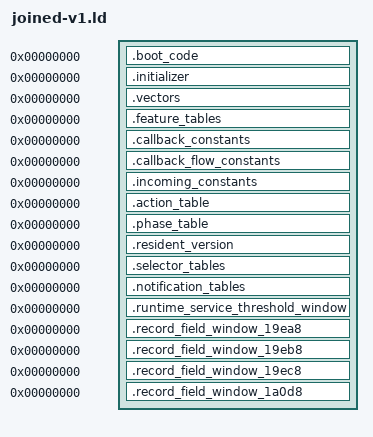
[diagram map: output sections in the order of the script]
OUTPUT_ARCH(riscv)
SECTIONS
{
 .boot_code 0 : SUBALIGN(2) { *(.boot_code)
  *(.text.tsl9_record_dispatch_provider_b584)
  *(.text.tsl9_remaining_record_dispatch_entry_b5f6)
  *(.text.tsl9_remaining_record_dispatch_block_b604)
  *(.text.tsl9_remaining_record_dispatch_block_b60a)
  *(.text.tsl9_remaining_record_dispatch_block_b616)
  *(.text.tsl9_remaining_record_dispatch_block_b618)
  *(.text.tsl9_remaining_record_dispatch_block_b628)
  *(.text.tsl9_remaining_record_dispatch_block_b63c)
  *(.text.tsl9_remaining_record_dispatch_block_b642)
  *(.text.tsl9_remaining_record_dispatch_block_b648)
  *(.text.tsl9_remaining_record_dispatch_block_b64e)
  *(.text.tsl9_remaining_record_dispatch_block_b650)
  *(.text.tsl9_remaining_record_dispatch_entry_b67a)
  *(.text.tsl9_remaining_record_dispatch_block_b680)
  *(.text.tsl9_remaining_record_dispatch_block_b68a)
  *(.text.tsl9_remaining_record_dispatch_block_b6a2)
  *(.text.tsl9_remaining_record_dispatch_entry_b6bc)
  *(.text.tsl9_remaining_record_dispatch_block_b6c2)
  *(.text.tsl9_remaining_record_dispatch_block_b6cc)
  *(.text.tsl9_remaining_record_dispatch_block_b6e4)
  *(.text.tsl9_feature_external_b730)
  *(.text.tsl9_remaining_record_dispatch_block_b744)
  *(.text.tsl9_remaining_record_dispatch_block_b74a)
  *(.text.tsl9_remaining_record_dispatch_block_b756)
  *(.text.tsl9_remaining_record_dispatch_block_b76a)
  *(.text.tsl9_remaining_record_dispatch_block_b776)
  *(.text.tsl9_remaining_record_dispatch_block_b790)
  *(.text.tsl9_remaining_record_dispatch_block_b7ac)
  *(.text.tsl9_remaining_record_dispatch_block_b7c6)
  *(.text.tsl9_remaining_record_dispatch_block_b7e2)
  *(.text.tsl9_remaining_record_dispatch_block_b7f0)
  *(.text.tsl9_remaining_record_dispatch_block_b800)
  *(.text.tsl9_remaining_record_dispatch_block_b808)
  *(.text.tsl9_remaining_record_dispatch_block_b80c)
  *(.text.tsl9_remaining_record_dispatch_block_b816)
  *(.text.tsl9_remaining_record_dispatch_block_b818)
  *(.text.tsl9_remaining_record_dispatch_block_b82c)
  *(.text.tsl9_remaining_record_dispatch_block_b838)
  *(.text.tsl9_remaining_record_dispatch_block_b846)
  *(.text.tsl9_remaining_record_dispatch_block_b84a)
  *(.text.tsl9_remaining_record_dispatch_block_b84e)
  *(.text.tsl9_remaining_record_dispatch_block_b85e)
  *(.text.tsl9_remaining_record_dispatch_block_b86e)
  *(.text.tsl9_remaining_record_dispatch_block_b872)
  *(.text.tsl9_remaining_record_dispatch_block_b878)
  *(.text.tsl9_remaining_record_dispatch_block_b890)
  *(.text.tsl9_remaining_record_dispatch_block_b892)
  *(.text.tsl9_remaining_record_dispatch_block_b898)
  *(.text.tsl9_remaining_record_dispatch_block_b89e)
  *(.text.tsl9_remaining_record_dispatch_block_b8ae)
  *(.text.tsl9_remaining_record_dispatch_block_b8b2)
  *(.text.tsl9_remaining_record_dispatch_block_b8b8)
  *(.text.tsl9_remaining_record_dispatch_block_b8c2)
  *(.text.tsl9_remaining_record_dispatch_block_b8c6)
  *(.text.tsl9_remaining_record_dispatch_block_b8cc)
  *(.text.tsl9_remaining_record_dispatch_block_b8d0)
  *(.text.tsl9_remaining_record_dispatch_block_b8da)
  *(.text.tsl9_remaining_record_dispatch_block_b8de)
  *(.text.tsl9_remaining_record_dispatch_block_b8e4)
  *(.text.tsl9_remaining_record_dispatch_block_b8e8)
  *(.text.tsl9_remaining_record_dispatch_block_b8ee)
  *(.text.tsl9_remaining_record_dispatch_block_b8f2)
  *(.text.tsl9_remaining_record_dispatch_block_b8f8)
  *(.text.tsl9_remaining_record_dispatch_block_b8fc)
  *(.text.tsl9_remaining_record_dispatch_block_b902)
  *(.text.tsl9_remaining_record_dispatch_block_b906)
  *(.text.tsl9_remaining_record_dispatch_block_b90c)
  *(.text.tsl9_remaining_record_dispatch_block_b910)
  *(.text.tsl9_remaining_record_dispatch_block_b91e)
  *(.text.tsl9_remaining_record_dispatch_block_b924)
  *(.text.tsl9_remaining_record_dispatch_block_b92e)
  *(.text.tsl9_remaining_record_dispatch_block_b934)
  *(.text.tsl9_remaining_record_dispatch_block_b940)
  *(.text.tsl9_remaining_record_dispatch_block_b946)
  *(.text.tsl9_remaining_record_dispatch_block_b952)
  *(.text.tsl9_remaining_record_dispatch_block_b958)
  *(.text.tsl9_remaining_record_dispatch_block_b964)
  *(.text.tsl9_remaining_record_dispatch_block_b96a)
  *(.text.tsl9_remaining_record_dispatch_block_b972)
  *(.text.tsl9_remaining_record_dispatch_block_b978)
  *(.text.tsl9_remaining_record_dispatch_block_b980)
  *(.text.tsl9_remaining_record_dispatch_block_b986)
  *(.text.tsl9_remaining_record_dispatch_block_b98e)
  *(.text.tsl9_remaining_record_dispatch_block_b994)
  *(.text.tsl9_remaining_record_dispatch_block_b9a0)
  *(.text.tsl9_remaining_record_dispatch_block_b9a4)
  *(.text.tsl9_remaining_record_dispatch_block_b9b0)
  *(.text.tsl9_remaining_record_dispatch_block_b9b4)
  *(.text.tsl9_remaining_record_dispatch_block_b9be)
  *(.text.tsl9_remaining_record_dispatch_block_b9c2)
  *(.text.tsl9_remaining_record_dispatch_block_b9ca)
  *(.text.tsl9_remaining_record_dispatch_block_b9ce)
  *(.text.tsl9_remaining_record_dispatch_block_b9d4)
  *(.text.tsl9_remaining_record_dispatch_block_b9e4)
  *(.text.tsl9_remaining_record_dispatch_block_b9f2)
  *(.text.tsl9_remaining_record_dispatch_block_b9fe)
  *(.text.tsl9_remaining_record_dispatch_block_ba02)
  *(.text.tsl9_remaining_record_dispatch_block_ba08)
  *(.text.tsl9_remaining_record_dispatch_block_ba14)
  *(.text.tsl9_remaining_record_dispatch_block_ba18)
  *(.text.tsl9_remaining_record_dispatch_block_ba1a)
  *(.text.tsl9_remaining_record_dispatch_block_ba20)
  *(.text.tsl9_remaining_record_dispatch_block_ba24)
  *(.text.tsl9_remaining_record_dispatch_block_ba28)
  *(.text.tsl9_remaining_record_dispatch_block_ba3a)
  *(.text.tsl9_remaining_record_dispatch_block_ba46)
  *(.text.tsl9_remaining_record_dispatch_block_ba4a)
  *(.text.tsl9_remaining_record_dispatch_block_ba50)
  *(.text.tsl9_remaining_record_dispatch_block_ba58)
  *(.text.tsl9_remaining_record_dispatch_block_ba5c)
  *(.text.tsl9_remaining_record_dispatch_block_ba70)
  *(.text.tsl9_remaining_record_dispatch_block_ba7e)
  *(.text.tsl9_remaining_record_dispatch_block_ba80)
  *(.text.tsl9_remaining_record_dispatch_block_ba94)
  *(.text.tsl9_remaining_record_dispatch_block_baa2)
  *(.text.tsl9_remaining_record_dispatch_block_baa4)
  *(.text.tsl9_remaining_record_dispatch_block_babe)
  *(.text.tsl9_remaining_record_dispatch_block_bac0)
  *(.text.tsl9_remaining_record_dispatch_block_bac4)
  *(.text.tsl9_remaining_record_dispatch_block_baca)
  *(.text.tsl9_remaining_record_dispatch_block_bad6)
  *(.text.tsl9_remaining_record_dispatch_block_bada)
  *(.text.tsl9_remaining_record_dispatch_block_badc)
  *(.text.tsl9_remaining_record_dispatch_block_bae2)
  *(.text.tsl9_remaining_record_dispatch_block_bae8)
  *(.text.tsl9_remaining_record_dispatch_block_baf2)
  *(.text.tsl9_remaining_record_dispatch_block_bafa)
  *(.text.tsl9_remaining_record_dispatch_block_bb06)
  *(.text.tsl9_remaining_record_dispatch_block_bb0a)
  *(.text.tsl9_remaining_record_dispatch_block_bb14)
  *(.text.tsl9_remaining_record_dispatch_block_bb18)
  *(.text.tsl9_remaining_record_dispatch_block_bb1a)
  *(.text.tsl9_remaining_record_dispatch_block_bb20)
  *(.text.tsl9_remaining_record_dispatch_block_bb28)
  *(.text.tsl9_remaining_record_dispatch_block_bb2c)
  *(.text.tsl9_remaining_record_dispatch_block_bb2e)
  *(.text.tsl9_remaining_record_dispatch_block_bb32)
  *(.text.tsl9_remaining_record_dispatch_block_bb3e)
  *(.text.tsl9_remaining_record_dispatch_block_bb40)
  *(.text.tsl9_remaining_record_dispatch_block_bb42)
  *(.text.tsl9_remaining_record_dispatch_block_bb4c)
  *(.text.tsl9_remaining_record_dispatch_block_bb50)
  *(.text.tsl9_remaining_record_dispatch_block_bb52)
  *(.text.tsl9_remaining_record_dispatch_block_bb58)
  *(.text.tsl9_remaining_record_dispatch_block_bb60)
  *(.text.tsl9_remaining_record_dispatch_block_bb64)
  *(.text.tsl9_remaining_record_dispatch_block_bb68)
  *(.text.tsl9_remaining_record_dispatch_block_bb72)
  *(.text.tsl9_remaining_record_dispatch_block_bb7c)
  *(.text.tsl9_remaining_record_dispatch_block_bb82)
  *(.text.tsl9_remaining_record_dispatch_block_bb88)
  *(.text.tsl9_remaining_record_dispatch_block_bb94)
  *(.text.tsl9_remaining_record_dispatch_block_bb9a)
  *(.text.tsl9_remaining_record_dispatch_block_bb9c)
  *(.text.tsl9_remaining_record_dispatch_block_bba0)
  *(.text.tsl9_remaining_record_dispatch_block_bba4)
  *(.text.tsl9_remaining_record_dispatch_block_bba8)
  *(.text.tsl9_remaining_record_dispatch_block_bbac)
  *(.text.tsl9_remaining_record_dispatch_block_bbb2)
  *(.text.tsl9_remaining_record_dispatch_block_bbb8)
  *(.text.tsl9_remaining_record_dispatch_block_bbbe)
  *(.text.tsl9_remaining_record_dispatch_block_bbc4)
  *(.text.tsl9_remaining_record_dispatch_block_bbce)
  *(.text.tsl9_remaining_record_dispatch_block_bbd4)
  *(.text.tsl9_remaining_record_dispatch_block_bbdc)
  *(.text.tsl9_remaining_record_dispatch_block_bbe0)
  *(.text.tsl9_remaining_record_dispatch_block_bbe2)
  *(.text.tsl9_remaining_record_dispatch_block_bbe6)
  *(.text.tsl9_remaining_record_dispatch_block_bbea)
  *(.text.tsl9_remaining_record_dispatch_block_bbf2)
  *(.text.tsl9_remaining_record_dispatch_block_bc06)
  *(.text.tsl9_remaining_record_dispatch_block_bc1a)
  *(.text.tsl9_remaining_record_dispatch_block_bc26)
  *(.text.tsl9_remaining_record_dispatch_block_bc30)
  *(.text.tsl9_remaining_record_dispatch_block_bc32)
  *(.text.tsl9_remaining_record_dispatch_block_bc42)
  *(.text.tsl9_remaining_record_dispatch_block_bc52)
  *(.text.tsl9_remaining_record_dispatch_block_bc56)
  *(.text.tsl9_remaining_record_dispatch_block_bc5c)
  *(.text.tsl9_remaining_record_dispatch_block_bc6e)
  *(.text.tsl9_remaining_record_dispatch_block_bc76)
  *(.text.tsl9_remaining_record_dispatch_block_bc84)
  *(.text.tsl9_remaining_record_dispatch_block_bc8c)
  *(.text.tsl9_remaining_record_dispatch_block_bc90)
  *(.text.tsl9_remaining_record_dispatch_block_bc96)
  *(.text.tsl9_remaining_record_dispatch_block_bcb0)
  *(.text.tsl9_remaining_record_dispatch_block_bcbc)
  *(.text.tsl9_remaining_record_dispatch_block_bcc0)
  *(.text.tsl9_remaining_record_dispatch_block_bcc2)
  *(.text.tsl9_remaining_record_dispatch_block_bcc6)
  *(.text.tsl9_remaining_record_dispatch_block_bcca)
  *(.text.tsl9_remaining_record_dispatch_block_bcd4)
  *(.text.tsl9_remaining_record_dispatch_block_bcde)
  *(.text.tsl9_record_dispatch_provider_bd3a)
  *(.text.tsl9_feature_external_bd88)
  *(.text.tsl9_remaining_record_dispatch_block_bda4)
  *(.text.tsl9_remaining_record_dispatch_block_bdaa)
  *(.text.tsl9_remaining_record_dispatch_block_bdb0)
  *(.text.tsl9_remaining_record_dispatch_block_bdb6)
  *(.text.tsl9_remaining_record_dispatch_block_bdc6)
  *(.text.tsl9_remaining_record_dispatch_block_bdd8)
  *(.text.tsl9_remaining_record_dispatch_block_bde6)
  *(.text.tsl9_remaining_record_dispatch_block_bdf6)
  *(.text.tsl9_remaining_record_dispatch_block_bdfc)
  *(.text.tsl9_remaining_record_dispatch_block_be0a)
  *(.text.tsl9_remaining_record_dispatch_block_be18)
  *(.text.tsl9_remaining_record_dispatch_block_be2a)
  *(.text.tsl9_remaining_record_dispatch_block_be3a)
  *(.text.tsl9_remaining_record_dispatch_block_be46)
  *(.text.tsl9_remaining_record_dispatch_block_be5c)
  *(.text.tsl9_remaining_record_dispatch_block_be70)
  *(.text.tsl9_remaining_record_dispatch_block_be78)
  *(.text.tsl9_remaining_record_dispatch_block_be82)
  *(.text.tsl9_remaining_record_dispatch_block_be98)
  *(.text.tsl9_remaining_record_dispatch_block_bea4)
  *(.text.tsl9_remaining_record_dispatch_block_beae)
  *(.text.tsl9_remaining_record_dispatch_block_bebe)
  *(.text.tsl9_remaining_record_dispatch_block_beec)
  *(.text.tsl9_remaining_record_dispatch_block_bef4)
  *(.text.tsl9_remaining_record_dispatch_block_bef8)
  *(.text.tsl9_remaining_record_dispatch_block_bf0e)
  *(.text.tsl9_remaining_record_dispatch_block_bf14)
  *(.text.tsl9_remaining_record_dispatch_block_bf1a)
  *(.text.tsl9_remaining_record_dispatch_block_bf24)
  *(.text.tsl9_remaining_record_dispatch_block_bf28)
  *(.text.tsl9_remaining_record_dispatch_block_bf3a)
  *(.text.tsl9_remaining_record_dispatch_block_bf42)
  *(.text.tsl9_remaining_record_dispatch_block_bf54)
  *(.text.tsl9_remaining_record_dispatch_block_bf56)
  *(.text.tsl9_remaining_record_dispatch_block_bf58)
  *(.text.tsl9_remaining_record_dispatch_block_bf5a)
  *(.text.tsl9_remaining_record_dispatch_block_bf64)
  *(.text.tsl9_remaining_record_dispatch_block_bf6e)
  *(.text.tsl9_remaining_record_dispatch_block_bf78)
  *(.text.tsl9_remaining_record_dispatch_block_bf80)
  *(.text.tsl9_remaining_record_dispatch_block_bf84)
  *(.text.tsl9_remaining_record_dispatch_block_bf86)
  *(.text.tsl9_remaining_record_dispatch_block_bf98)
  *(.text.tsl9_remaining_record_dispatch_block_bf9c)
  *(.text.tsl9_remaining_record_dispatch_block_bfb4)
  *(.text.tsl9_remaining_record_dispatch_block_bfc0)
  *(.text.tsl9_remaining_record_dispatch_block_bfd0)
  *(.text.tsl9_remaining_record_dispatch_block_bfdc)
  *(.text.tsl9_remaining_record_dispatch_block_bfe6)
  *(.text.tsl9_remaining_record_dispatch_block_bff8)
  *(.text.tsl9_remaining_record_dispatch_block_c01a)
  *(.text.tsl9_remaining_record_dispatch_block_c024)
  *(.text.tsl9_remaining_record_dispatch_block_c058)
  *(.text.tsl9_remaining_record_dispatch_block_c05e)
  *(.text.tsl9_remaining_record_dispatch_block_c066)
  *(.text.tsl9_remaining_record_dispatch_block_c068)
  *(.text.tsl9_remaining_record_dispatch_block_c07c)
  *(.text.tsl9_remaining_record_dispatch_block_c090)
  *(.text.tsl9_remaining_record_dispatch_block_c094)
  *(.text.tsl9_remaining_record_dispatch_block_c096)
  *(.text.tsl9_remaining_record_dispatch_block_c0aa)
  *(.text.tsl9_remaining_record_dispatch_block_c0b4)
  *(.text.tsl9_remaining_record_dispatch_block_c0d2)
  *(.text.tsl9_remaining_record_dispatch_block_c0e4)
  *(.text.tsl9_remaining_record_dispatch_block_c0f4)
  *(.text.tsl9_remaining_record_dispatch_block_c104)
  *(.text.tsl9_remaining_record_dispatch_block_c10e)
  *(.text.tsl9_remaining_record_dispatch_block_c11a)
  *(.text.tsl9_remaining_record_dispatch_block_c120)
  *(.text.tsl9_remaining_record_dispatch_block_c12c)
  *(.text.tsl9_remaining_record_dispatch_block_c148)
  *(.text.tsl9_remaining_record_dispatch_block_c15a)
  *(.text.tsl9_remaining_record_dispatch_block_c15e)
  *(.text.tsl9_remaining_record_dispatch_block_c160)
  *(.text.tsl9_remaining_record_dispatch_block_c172)
  *(.text.tsl9_remaining_record_dispatch_block_c184)
  *(.text.tsl9_remaining_record_dispatch_block_c190)
  *(.text.tsl9_remaining_record_dispatch_block_c194)
  *(.text.tsl9_remaining_record_dispatch_block_c19a)
  *(.text.tsl9_remaining_record_dispatch_block_c19c)
  *(.text.tsl9_remaining_record_dispatch_block_c1ac)
  *(.text.tsl9_remaining_record_dispatch_block_c1be)
  *(.text.tsl9_remaining_record_dispatch_block_c1c8)
  *(.text.tsl9_remaining_record_dispatch_block_c1ce)
  *(.text.tsl9_remaining_record_dispatch_block_c1d8)
  *(.text.tsl9_remaining_record_dispatch_block_c1e4)
  *(.text.tsl9_remaining_record_dispatch_block_c1ea)
  *(.text.tsl9_remaining_record_dispatch_block_c1f8)
  *(.text.tsl9_remaining_record_dispatch_block_c204)
  *(.text.tsl9_remaining_record_dispatch_block_c20a)
  *(.text.tsl9_remaining_record_dispatch_block_c216)
  *(.text.tsl9_remaining_record_dispatch_block_c220)
  *(.text.tsl9_remaining_record_dispatch_block_c22c)
  *(.text.tsl9_remaining_record_dispatch_block_c23a)
  *(.text.tsl9_remaining_record_dispatch_block_c248)
  *(.text.tsl9_remaining_record_dispatch_block_c256)
  *(.text.tsl9_remaining_record_dispatch_block_c25c)
  *(.text.tsl9_remaining_record_dispatch_block_c27a)
  *(.text.tsl9_remaining_record_dispatch_block_c284)
  *(.text.tsl9_remaining_record_dispatch_block_c294)
  *(.text.tsl9_remaining_record_dispatch_block_c2a6)
  *(.text.tsl9_remaining_record_dispatch_block_c2aa)
  *(.text.tsl9_remaining_record_dispatch_block_c2b2)
  *(.text.tsl9_remaining_record_dispatch_block_c2b6)
  *(.text.tsl9_remaining_record_dispatch_block_c2b8)
  *(.text.tsl9_remaining_record_dispatch_block_c2be)
  *(.text.tsl9_remaining_record_dispatch_block_c2c0)
  *(.text.tsl9_remaining_record_dispatch_block_c2ca)
  *(.text.tsl9_remaining_record_dispatch_block_c2d4)
  *(.text.tsl9_remaining_record_dispatch_block_c2de)
  *(.text.tsl9_remaining_record_dispatch_block_c2f8)
  *(.text.tsl9_remaining_record_dispatch_block_c308)
  *(.text.tsl9_remaining_record_dispatch_block_c318)
  *(.text.tsl9_remaining_record_dispatch_block_c324)
  *(.text.tsl9_remaining_record_dispatch_block_c32a)
  *(.text.tsl9_remaining_record_dispatch_block_c338)
  *(.text.tsl9_remaining_record_dispatch_block_c348)
  *(.text.tsl9_record_dispatch_provider_ce88)
  *(.text.tsl9_remaining_record_dispatch_block_ce98)
  *(.text.tsl9_remaining_record_dispatch_block_cea4)
  *(.text.tsl9_remaining_record_dispatch_entry_d868)
  *(.text.tsl9_remaining_record_dispatch_block_d86a)
  *(.text.tsl9_remaining_record_dispatch_block_d870)
  *(.text.tsl9_remaining_record_dispatch_block_d88a)
  *(.text.tsl9_remaining_record_dispatch_block_d88c)
  *(.text.tsl9_remaining_record_dispatch_block_d892)
  *(.text.tsl9_remaining_record_dispatch_block_d896)
  *(.text.tsl9_remaining_record_dispatch_block_d898)
  *(.text.tsl9_remaining_record_dispatch_block_d89c)
  *(.text.tsl9_remaining_record_dispatch_block_d8a6)
  *(.text.tsl9_remaining_record_dispatch_block_d8a8)
  *(.text.tsl9_remaining_record_dispatch_block_d8b0)
  *(.text.tsl9_remaining_record_dispatch_block_d8c2)
  *(.text.tsl9_remaining_record_dispatch_block_d8ca)
  *(.text.tsl9_remaining_record_dispatch_block_d8da)
  *(.text.tsl9_remaining_record_dispatch_block_d8dc)
  *(.text.tsl9_remaining_record_dispatch_entry_d8e2)
  *(.text.tsl9_remaining_record_dispatch_block_d8f2)
  *(.text.tsl9_remaining_record_dispatch_block_d902)
  *(.text.tsl9_remaining_record_dispatch_block_d90a)
  *(.text.tsl9_remaining_record_dispatch_entry_d90e)
  *(.text.tsl9_remaining_record_dispatch_block_d91e)
  *(.text.tsl9_remaining_record_dispatch_block_d926)
  *(.text.tsl9_remaining_record_dispatch_block_d92a)
  *(.text.tsl9_remaining_record_dispatch_block_d93a)
  *(.text.tsl9_remaining_record_dispatch_block_d94c)
  *(.text.tsl9_remaining_record_dispatch_block_d954)
  *(.text.tsl9_remaining_record_dispatch_entry_d956)
  *(.text.tsl9_remaining_record_dispatch_block_d95e)
  *(.text.tsl9_remaining_record_dispatch_block_d962)
  *(.text.tsl9_remaining_record_dispatch_block_d970)
  *(.text.tsl9_remaining_record_dispatch_block_d97c)
  *(.text.tsl9_remaining_record_dispatch_block_d984)
  *(.text.tsl9_remaining_record_dispatch_block_d988)
  *(.text.tsl9_remaining_record_dispatch_block_d98a)
  *(.text.tsl9_remaining_record_dispatch_block_d990)
  *(.text.tsl9_remaining_record_dispatch_block_d9a4)
  *(.text.tsl9_remaining_record_dispatch_block_d9ac)
  *(.text.tsl9_remaining_record_dispatch_block_d9b2)
  *(.text.tsl9_remaining_record_dispatch_block_d9be)
  *(.text.tsl9_remaining_record_dispatch_block_d9c2)
  *(.text.tsl9_remaining_record_dispatch_block_d9c8)
  *(.text.tsl9_remaining_record_dispatch_block_d9ca)
  *(.text.tsl9_remaining_record_dispatch_block_d9d8)
  *(.text.tsl9_remaining_record_dispatch_block_d9e4)
  *(.text.tsl9_remaining_record_dispatch_block_d9f0)
  *(.text.tsl9_remaining_record_dispatch_block_d9fc)
  *(.text.tsl9_remaining_record_dispatch_block_da02)
  *(.text.tsl9_remaining_record_dispatch_block_da16)
  *(.text.tsl9_remaining_record_dispatch_block_da1c)
  *(.text.tsl9_remaining_record_dispatch_block_da24)
  *(.text.tsl9_remaining_record_dispatch_block_da2e)
  *(.text.tsl9_remaining_record_dispatch_block_da34)
  *(.text.tsl9_feature_external_da74)
  *(.text.tsl9_remaining_record_dispatch_block_da7e)
  *(.text.tsl9_remaining_record_dispatch_block_da8c)
  *(.text.tsl9_remaining_record_dispatch_block_da9e)
  *(.text.tsl9_remaining_record_dispatch_block_daae)
  *(.text.tsl9_remaining_record_dispatch_block_dac6)
  *(.text.tsl9_feature_external_dac8)
  *(.text.tsl9_remaining_record_dispatch_block_daea)
  *(.text.tsl9_remaining_record_dispatch_block_db04)
  *(.text.tsl9_remaining_record_dispatch_block_db1e)
  *(.text.tsl9_remaining_record_dispatch_block_db20)
  *(.text.tsl9_remaining_record_dispatch_block_db32)
  *(.text.tsl9_remaining_record_dispatch_block_db3c)
  *(.text.tsl9_remaining_record_dispatch_block_db42)
  *(.text.tsl9_remaining_record_dispatch_block_db5c)
  *(.text.tsl9_remaining_record_dispatch_block_db6e)
  *(.text.tsl9_remaining_record_dispatch_block_db76)
  *(.text.tsl9_remaining_record_dispatch_block_db80)
  *(.text.tsl9_remaining_record_dispatch_block_db92)
  *(.text.tsl9_remaining_record_dispatch_block_db9e)
  *(.text.tsl9_remaining_record_dispatch_block_dbb8)
  *(.text.tsl9_remaining_record_dispatch_block_dbba)
  *(.text.tsl9_remaining_record_dispatch_block_dbbe)
  *(.text.tsl9_remaining_record_dispatch_block_dbc0)
  *(.text.tsl9_remaining_record_dispatch_block_dbc4)
  *(.text.tsl9_feature_external_dbcc)
  *(.text.tsl9_remaining_record_dispatch_block_dbd8)
  *(.text.tsl9_remaining_record_dispatch_block_dbee)
  *(.text.tsl9_remaining_record_dispatch_block_dc00)
  *(.text.tsl9_remaining_record_dispatch_block_dc14)
  *(.text.tsl9_remaining_record_dispatch_block_dc1e)
  *(.text.tsl9_remaining_record_dispatch_block_dc22)
  *(.text.tsl9_remaining_record_dispatch_block_dc36)
  *(.text.tsl9_remaining_record_dispatch_block_dc42)
  *(.text.tsl9_remaining_record_dispatch_block_dc44)
  *(.text.tsl9_remaining_record_dispatch_block_dc50)
  *(.text.tsl9_remaining_record_dispatch_block_dc64)
  *(.text.tsl9_remaining_record_dispatch_block_dc6e)
  *(.text.tsl9_remaining_record_dispatch_block_dc74)
  *(.text.tsl9_remaining_record_dispatch_block_dc80)
  *(.text.tsl9_remaining_record_dispatch_block_dc82)
  *(.text.tsl9_remaining_record_dispatch_block_dc8e)
  *(.text.tsl9_remaining_record_dispatch_block_dca2)
  *(.text.tsl9_remaining_record_dispatch_block_dcb8)
  *(.text.tsl9_remaining_record_dispatch_block_dcc4)
  *(.text.tsl9_remaining_record_dispatch_block_dcc6)
  *(.text.tsl9_remaining_record_dispatch_block_dcd4)
  *(.text.tsl9_remaining_record_dispatch_block_dce8)
  *(.text.tsl9_remaining_record_dispatch_block_dd10)
  *(.text.tsl9_remaining_record_dispatch_block_dd1c)
  *(.text.tsl9_remaining_record_dispatch_block_dd1e)
  *(.text.tsl9_remaining_record_dispatch_block_dd2a)
  *(.text.tsl9_remaining_record_dispatch_block_dd38)
  *(.text.tsl9_remaining_record_dispatch_block_dd48)
  *(.text.tsl9_remaining_record_dispatch_block_dd4c)
  *(.text.tsl9_remaining_record_dispatch_block_dd5a)
  *(.text.tsl9_remaining_record_dispatch_block_dd62)
  *(.text.tsl9_remaining_record_dispatch_block_dd66)
  *(.text.tsl9_remaining_record_dispatch_block_dd86)
  *(.text.tsl9_remaining_record_dispatch_block_dd8c)
  *(.text.tsl9_remaining_record_dispatch_block_dd9e)
  *(.text.tsl9_remaining_record_dispatch_block_ddaa)
  *(.text.tsl9_remaining_record_dispatch_block_ddcc)
  *(.text.tsl9_remaining_record_dispatch_block_ddde)
  *(.text.tsl9_remaining_record_dispatch_block_ddea)
  *(.text.tsl9_remaining_record_dispatch_block_ddec)
  *(.text.tsl9_remaining_record_dispatch_block_ddfa)
  *(.text.tsl9_remaining_record_dispatch_block_de04)
  *(.text.tsl9_remaining_record_dispatch_block_de10)
  *(.text.tsl9_remaining_record_dispatch_block_de32)
  *(.text.tsl9_remaining_record_dispatch_block_de36)
  *(.text.tsl9_remaining_record_dispatch_block_de44)
  *(.text.tsl9_remaining_record_dispatch_block_de50)
  *(.text.tsl9_remaining_record_dispatch_block_de5c)
  *(.text.tsl9_remaining_record_dispatch_block_de68)
  *(.text.tsl9_remaining_record_dispatch_block_de76)
  *(.text.tsl9_remaining_record_dispatch_block_de80)
  *(.text.tsl9_record_dispatch_provider_deec)
  *(.text.tsl9_feature_external_def2)
  *(.text.tsl9_remaining_record_dispatch_block_df1a)
  *(.text.tsl9_remaining_record_dispatch_block_df1e)
  *(.text.tsl9_remaining_record_dispatch_block_df26)
  *(.text.tsl9_remaining_record_dispatch_block_df48)
  *(.text.tsl9_remaining_record_dispatch_block_df4a)
  *(.text.tsl9_remaining_record_dispatch_block_df4e)
  *(.text.tsl9_remaining_record_dispatch_block_df66)
  *(.text.tsl9_remaining_record_dispatch_block_df6e)
  *(.text.tsl9_remaining_record_dispatch_block_df74)
  *(.text.tsl9_remaining_record_dispatch_block_df76)
  *(.text.tsl9_remaining_record_dispatch_block_df92)
  *(.text.tsl9_remaining_record_dispatch_block_df94)
  *(.text.tsl9_remaining_record_dispatch_block_df98)
  *(.text.tsl9_remaining_record_dispatch_block_dfa4)
  *(.text.tsl9_remaining_record_dispatch_block_dfbe)
  *(.text.tsl9_remaining_record_dispatch_block_dfd8)
  *(.text.tsl9_remaining_record_dispatch_block_dff2)
  *(.text.tsl9_remaining_record_dispatch_block_e016)
  *(.text.tsl9_remaining_record_dispatch_block_e01a)
  *(.text.tsl9_remaining_record_dispatch_block_e028)
  *(.text.tsl9_remaining_record_dispatch_block_e030)
  *(.text.tsl9_record_dispatch_provider_e042)
  *(.text.tsl9_record_dispatch_provider_e048)
  *(.text.tsl9_record_dispatch_provider_f0c6)
  *(.text.tsl9_record_dispatch_provider_f630)
  *(.text.tsl9_record_dispatch_provider_f63c)
  *(.text.tsl9_record_dispatch_provider_f7dc)
  *(.text.tsl9_record_dispatch_provider_f7ec)
  *(.text.tsl9_record_dispatch_provider_f800)
  *(.text.tsl9_record_dispatch_provider_f80a)
  *(.text.tsl9_feature_external_f860)
  *(.text.tsl9_remaining_record_dispatch_block_f87a)
  *(.text.tsl9_remaining_record_dispatch_block_f888)
  *(.text.tsl9_remaining_record_dispatch_block_f88c)
  *(.text.tsl9_remaining_record_dispatch_block_f89a)
  *(.text.tsl9_remaining_record_dispatch_block_f8ae)
  *(.text.tsl9_remaining_record_dispatch_block_f8be)
  *(.text.tsl9_remaining_record_dispatch_block_f8e2)
  *(.text.tsl9_remaining_record_dispatch_block_f8e8)
  *(.text.tsl9_remaining_record_dispatch_block_f8f0)
  *(.text.tsl9_remaining_record_dispatch_block_f8f6)
  *(.text.tsl9_remaining_record_dispatch_block_f90a)
  *(.text.tsl9_remaining_record_dispatch_block_f916)
  *(.text.tsl9_remaining_record_dispatch_block_f920)
  *(.text.tsl9_remaining_record_dispatch_block_f938)
  *(.text.tsl9_remaining_record_dispatch_block_f94c)
  *(.text.tsl9_remaining_record_dispatch_block_f952)
  *(.text.tsl9_remaining_record_dispatch_block_f95c)
  *(.text.tsl9_remaining_record_dispatch_block_f966)
  *(.text.tsl9_remaining_record_dispatch_block_f970)
  *(.text.tsl9_remaining_record_dispatch_block_f972)
  *(.text.tsl9_record_dispatch_provider_f998)
  *(.text.tsl9_remaining_record_dispatch_block_f99e)
  *(.text.tsl9_remaining_record_dispatch_block_f9a2)
  *(.text.tsl9_remaining_record_dispatch_block_f9a4)
  *(.text.tsl9_remaining_record_dispatch_block_f9b2)
  *(.text.tsl9_remaining_record_dispatch_block_f9b8)
  *(.text.tsl9_remaining_record_dispatch_block_f9bc)
  *(.text.tsl9_remaining_record_dispatch_block_f9c2)
  *(.text.tsl9_remaining_record_dispatch_block_f9c6)
  *(.text.tsl9_remaining_record_dispatch_block_f9cc)
  *(.text.tsl9_remaining_record_dispatch_block_f9d8)
  *(.text.tsl9_remaining_record_dispatch_block_f9de)
  *(.text.tsl9_remaining_record_dispatch_block_f9e4)
  *(.text.tsl9_remaining_record_dispatch_block_f9ea)
  *(.text.tsl9_record_dispatch_provider_fa24)
  *(.text.tsl9_record_dispatch_provider_fa30)
  *(.text.tsl9_feature_external_fa62)
  *(.text.tsl9_remaining_record_dispatch_block_fa72)
  *(.text.tsl9_remaining_record_dispatch_block_fa7a)
  *(.text.tsl9_feature_external_fa7c)
  *(.text.tsl9_remaining_record_dispatch_block_fa86)
  *(.text.tsl9_remaining_record_dispatch_block_fa8c)
  *(.text.tsl9_remaining_record_dispatch_block_fa8e)
  *(.text.tsl9_remaining_record_dispatch_block_fa9c)
  *(.text.tsl9_remaining_record_dispatch_block_faa4)
  *(.text.tsl9_remaining_record_dispatch_block_fab0)
  *(.text.tsl9_remaining_record_dispatch_block_fac0)
  *(.text.tsl9_remaining_record_dispatch_block_fac4)
  *(.text.tsl9_remaining_record_dispatch_block_face)
  *(.text.tsl9_remaining_record_dispatch_block_fad6)
  *(.text.tsl9_remaining_record_dispatch_block_fae2)
  *(.text.tsl9_remaining_record_dispatch_block_fae4)
  *(.text.tsl9_record_dispatch_provider_fae6)
  *(.text.tsl9_record_dispatch_provider_faf2)
  *(.text.tsl9_feature_external_ff56)
  *(.text.tsl9_remaining_record_dispatch_block_ff5c)
  *(.text.tsl9_remaining_record_dispatch_block_ff66)
  *(.text.tsl9_remaining_record_dispatch_block_ff76)
  *(.text.tsl9_remaining_record_dispatch_block_ff7a)
  *(.text.tsl9_remaining_record_dispatch_block_ff8a)
  *(.text.tsl9_remaining_record_dispatch_block_ff8e)
  *(.text.tsl9_remaining_record_dispatch_block_ff96)
  *(.text.tsl9_remaining_record_dispatch_block_ffa2)
  *(.text.tsl9_feature_external_ffa4)
  *(.text.tsl9_remaining_record_dispatch_block_ffaa)
  *(.text.tsl9_remaining_record_dispatch_block_ffb0)
  *(.text.tsl9_remaining_record_dispatch_block_ffc8)
  *(.text.tsl9_remaining_record_dispatch_block_ffcc)
  *(.text.tsl9_remaining_record_dispatch_block_ffd2)
  *(.text.tsl9_remaining_record_dispatch_block_ffde)
  *(.text.tsl9_remaining_record_dispatch_block_fffc)
  *(.text.tsl9_remaining_record_dispatch_block_10002)
  *(.text.tsl9_remaining_record_dispatch_block_10008)
  *(.text.tsl9_remaining_record_dispatch_block_1000e)
  *(.text.tsl9_remaining_record_dispatch_block_10014)
  *(.text.tsl9_remaining_record_dispatch_block_1001a)
  *(.text.tsl9_remaining_record_dispatch_block_10020)
  *(.text.tsl9_remaining_record_dispatch_entry_181a0)
  *(.text.tsl9_remaining_record_dispatch_block_181a8)
  *(.text.tsl9_remaining_record_dispatch_block_181aa)
  *(.text.tsl9_remaining_record_dispatch_block_181b6)
  *(.text.tsl9_remaining_record_dispatch_block_181be)
  *(.text.tsl9_remaining_record_dispatch_entry_181ce)
  *(.text.tsl9_remaining_record_dispatch_block_181d0)
  *(.text.tsl9_remaining_record_dispatch_block_181de)
  *(.text.tsl9_remaining_record_dispatch_block_181e6)
  *(.text.tsl9_remaining_record_dispatch_block_181ee)
  *(.text.tsl9_remaining_record_dispatch_block_181f0)
  *(.text.tsl9_remaining_record_dispatch_block_18204)
  *(.text.tsl9_remaining_record_dispatch_block_18216)
 }
 .initializer 0 : SUBALIGN(4) { *(.initializer) }
 .vectors 0 : SUBALIGN(4) { *(.vectors) }
 .feature_tables 0 : SUBALIGN(4) { *(.feature_tables) }
 .callback_constants 0 : SUBALIGN(4) { *(.callback_constants) }
 .callback_flow_constants 0 : SUBALIGN(4) { *(.callback_flow_constants) }
 .incoming_constants 0 : SUBALIGN(4) { *(.incoming_constants) }
 .action_table 0 : SUBALIGN(4) { *(.action_table) }
 .phase_table 0 : SUBALIGN(4) { *(.phase_table) }
 .resident_version 0 : SUBALIGN(4) { *(.resident_version) }
 .selector_tables 0 : SUBALIGN(1) {
  *(.rodata.tsl9_feature_state_records_static_data_1a4e4)
  *(.rodata.tsl9_feature_state_records_static_data_1a518)
  *(.rodata.tsl9_feature_state_records_static_data_1a528)
  *(.rodata.tsl9_feature_state_records_static_data_1a538)
 }
 .notification_tables 0 : SUBALIGN(4) {
  *(.rodata.tsl9_selector_notifications_table_1a13c)
  *(.rodata.tsl9_selector_notifications_table_1a150)
  *(.rodata.tsl9_selector_notifications_table_1a1c8)
  *(.rodata.tsl9_selector_notifications_table_1a314)
  *(.rodata.tsl9_selector_notifications_table_1a33c)
 }
 .runtime_service_threshold_window 0 : SUBALIGN(1) { *(.runtime_service_threshold_window) }
 .record_field_window_19ea8 0 : SUBALIGN(1) { *(.record_field_window_19ea8) }
 .record_field_window_19eb8 0 : SUBALIGN(1) { *(.record_field_window_19eb8) }
 .record_field_window_19ec8 0 : SUBALIGN(1) { *(.record_field_window_19ec8) }
 .record_field_window_1a0d8 0 : SUBALIGN(1) { *(.record_field_window_1a0d8) }
 /DISCARD/ : { *(.comment) *(.riscv.attributes) *(.llvm_addrsig) }
}
